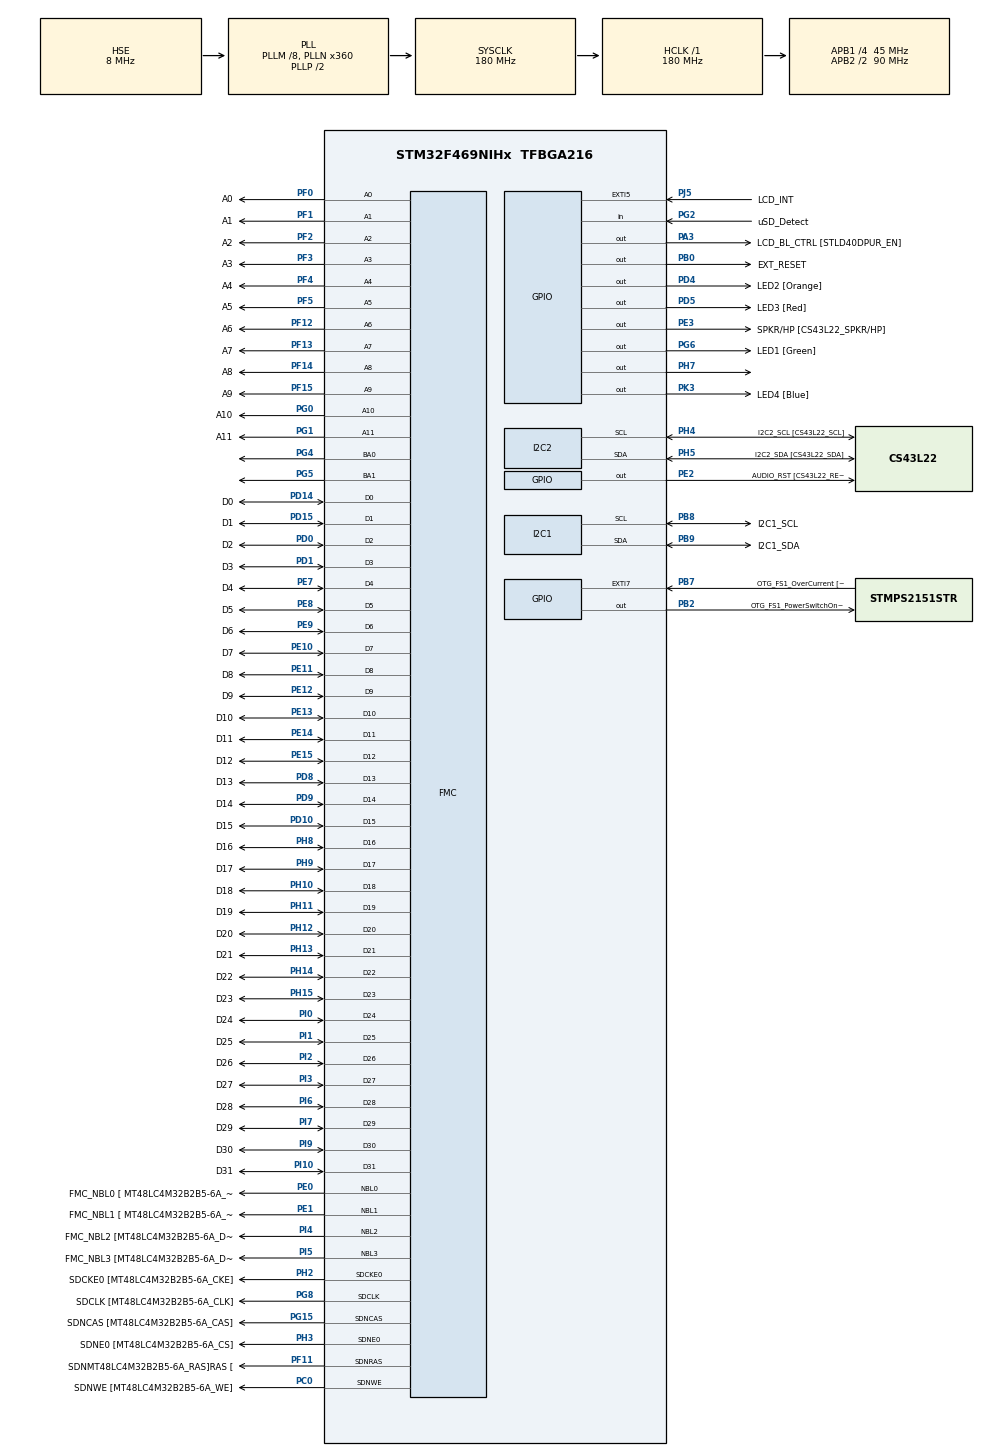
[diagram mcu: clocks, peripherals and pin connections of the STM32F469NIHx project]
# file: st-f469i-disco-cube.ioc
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PF5.GPIO_PuPd=GPIO_NOPULL
PC10.GPIO_PuPd=GPIO_NOPULL
FMC.SDClockPeriod1=FMC_SDRAM_CLOCK_PERIOD_2
SH.FMC_A0.0=FMC_A0,12b-sda1
PB10.GPIO_PuPd=GPIO_PULLUP
PH15.GPIO_Label=D23
NVIC.TIM6_DAC_IRQn=true\:0\:0\:false\:false\:true\:false\:true
PA10.GPIO_PuPd=GPIO_NOPULL
PG8.Signal=FMC_SDCLK
DSIHOST_D0N.Mode=DSIHost_Video
PG0.Signal=FMC_A10
PA3.GPIO_PuPd=GPIO_NOPULL
PE8.GPIO_Speed_High_Default=GPIO_SPEED_FREQ_VERY_HIGH
PE10.GPIO_PuPd=GPIO_NOPULL
PD10.GPIO_PuPd=GPIO_NOPULL
SH.FMC_D5_DA5.0=FMC_D5,sd-32b-d1
PF10.GPIO_PuPd=GPIO_NOPULL
PI10.GPIO_PuPd=GPIO_NOPULL
PH10.GPIO_PuPd=GPIO_NOPULL
PH13.GPIO_Mode=GPIO_MODE_AF_PP
SH.FMC_D9_DA9.0=FMC_D9,sd-32b-d1
PD0.GPIO_Speed_High_Default=GPIO_SPEED_FREQ_VERY_HIGH
DSIHOST_D0P.Signal=DSIHOST_D0P
SH.FMC_D25.0=FMC_D25,sd-32b-d1
PE13.GPIO_Mode=GPIO_MODE_AF_PP
PF13.GPIO_Mode=GPIO_MODE_AF_PP
PG15.GPIO_Label=SDNCAS [MT48LC4M32B2B5-6A_CAS]
PF7.Signal=QUADSPI_BK1_IO2
NVIC.DMA2D_IRQn=true\:0\:0\:false\:false\:true\:true\:true
SH.FMC_SDNWE.0=FMC_SDNWE,12b-sda1
PH9.Signal=FMC_D17
PG7.GPIO_Mode=GPIO_MODE_AF_PP
SH.FMC_D11_DA11.0=FMC_D11,sd-32b-d1
PD9.GPIO_Speed_High_Default=GPIO_SPEED_FREQ_VERY_HIGH
RCC.APB2TimFreq_Value=180000000
PB6.Signal=QUADSPI_BK1_NCS
PD0.Signal=FMC_D2_DA2
PD8.Signal=FMC_D13_DA13
PE1.Signal=FMC_NBL1
PI5.GPIO_Mode=GPIO_MODE_AF_PP
PF1.GPIO_Label=A1
PI4.GPIO_Label=FMC_NBL2 [MT48LC4M32B2B5-6A_DQM2]
PD1.GPIO_Label=D3
FMC.SelfRefreshTime1=4
PF12.GPIO_Label=A6
LTDC.PixelFormat_L0=LTDC_PIXEL_FORMAT_RGB888
PE9.Signal=FMC_D6_DA6
DSIHOST_D1N.Signal=DSIHOST_D1N
SH.FMC_A2.0=FMC_A2,12b-sda1
PE4.GPIO_Label=SAI1_FSA [CS43L22_LRCK]
PD14.GPIO_PuPd=GPIO_NOPULL
SH.FMC_D1_DA1.0=FMC_D1,sd-32b-d1
PK3.GPIO_ModeDefaultOutputPP=GPIO_MODE_OUTPUT_OD
PH14.GPIO_PuPd=GPIO_NOPULL
PF1.GPIO_Mode=GPIO_MODE_AF_PP
PF14.GPIO_PuPd=GPIO_NOPULL
PG0.GPIO_PuPd=GPIO_NOPULL
PH3.GPIO_PuPd=GPIO_NOPULL
PI2.GPIO_PuPd=GPIO_NOPULL
PE9.GPIO_Mode=GPIO_MODE_AF_PP
Mcu.Package=TFBGA216
PB9.Signal=I2C1_SDA
NVIC.TimeBase=TIM6_DAC_IRQn
PI9.GPIO_Mode=GPIO_MODE_AF_PP
PI2.GPIO_Speed_High_Default=GPIO_SPEED_FREQ_VERY_HIGH
NVIC.TimeBaseIP=TIM6
PA10.Signal=USB_OTG_FS_ID
SH.FMC_D27.0=FMC_D27,sd-32b-d1
PE12.GPIO_Label=D9
FMC.WriteRecoveryTime1=3
RCC.APB2CLKDivider=RCC_HCLK_DIV2
PH3.GPIO_Speed_High_Default=GPIO_SPEED_FREQ_VERY_HIGH
RCC.APB1TimFreq_Value=90000000
PD5.GPIO_Speed=GPIO_SPEED_FREQ_LOW
PH5.GPIO_Speed=GPIO_SPEED_FREQ_VERY_HIGH
PB0.GPIO_ModeDefaultOutputPP=GPIO_MODE_OUTPUT_PP
FMC.RowCycleDelay1=7
DSIHOST_D1P.GPIO_Label=DSI_D1_P
PF9.GPIO_PuPd=GPIO_NOPULL
PD15.Signal=FMC_D1_DA1
PE7.GPIO_Speed_High_Default=GPIO_SPEED_FREQ_VERY_HIGH
PC8.GPIO_Mode=GPIO_MODE_AF_PP
PI5.GPIO_PuPd=GPIO_NOPULL
SH.FMC_A4.0=FMC_A4,12b-sda1
PH10.GPIO_Speed_High_Default=GPIO_SPEED_FREQ_VERY_HIGH
PH13.Signal=FMC_D21
PI3.GPIO_Speed_High_Default=GPIO_SPEED_FREQ_VERY_HIGH
PD1.GPIO_Speed_High_Default=GPIO_SPEED_FREQ_VERY_HIGH
PF4.GPIO_Mode=GPIO_MODE_AF_PP
PG5.Signal=FMC_A15_BA1
PE9.GPIO_Speed_High_Default=GPIO_SPEED_FREQ_VERY_HIGH
SH.FMC_D10_DA10.0=FMC_D10,sd-32b-d1
PB6.GPIO_PuPd=GPIO_NOPULL
PI6.GPIO_PuPd=GPIO_NOPULL
SH.FMC_D16.0=FMC_D16,sd-32b-d1
PF5.GPIO_Mode=GPIO_MODE_AF_PP
PG8.GPIO_PuPd=GPIO_NOPULL
PF8.GPIO_Label=QSPI_BK1_IO0 [N25Q128A13EF840F_DQ0]
PD10.Signal=FMC_D15_DA15
PB8.GPIO_Label=I2C1_SCL
PC10.GPIO_Mode=GPIO_MODE_AF_PP
PB10.GPIO_Mode=GPIO_MODE_AF_PP
PE15.GPIO_Speed_High_Default=GPIO_SPEED_FREQ_VERY_HIGH
SH.FMC_D29.0=FMC_D29,sd-32b-d1
PE8.GPIO_Label=D5
PH11.GPIO_Label=D19
PF5.GPIO_Speed_High_Default=GPIO_SPEED_FREQ_VERY_HIGH
PE2.GPIO_PuPd=GPIO_NOPULL
PI0.GPIO_Speed_High_Default=GPIO_SPEED_FREQ_VERY_HIGH
PF10.GPIO_Mode=GPIO_MODE_AF_PP
PE1.GPIO_Label=FMC_NBL1 [ MT48LC4M32B2B5-6A_DQM1]
PD14.GPIO_Speed_High_Default=GPIO_SPEED_FREQ_VERY_HIGH
PF13.GPIO_PuPd=GPIO_NOPULL
PI7.Signal=FMC_D29
FMC.ReadBurst1=FMC_SDRAM_RBURST_ENABLE
SH.FMC_A6.0=FMC_A6,12b-sda1
PE14.Signal=FMC_D11_DA11
PD4.GPIO_Speed=GPIO_SPEED_FREQ_LOW
PH4.GPIO_Speed=GPIO_SPEED_FREQ_VERY_HIGH
PG7.GPIO_Label=SAI1_MCLKA [CS43L22_MCLK]
PI2.Signal=FMC_D26
PF4.GPIO_Label=A4
PC9.GPIO_PuPd=GPIO_NOPULL
PE3.GPIO_PuPd=GPIO_NOPULL
PF13.Signal=FMC_A7
PG14.GPIO_PuPd=GPIO_NOPULL
SH.FMC_NBL2.0=FMC_NBL2,Sd4ByteEnable1
SH.FMC_D18.0=FMC_D18,sd-32b-d1
PC8.GPIO_PuPd=GPIO_NOPULL
PE5.GPIO_Label=SAI1_SCKA [CS43L22_CLK]
PC12.GPIO_Label=uSD_CLK
ProjectManager.HeapSize=0x200
DSIHOST_CKP.GPIO_Label=DSI_CK_P
PD0.GPIO_PuPd=GPIO_NOPULL
NVIC.PriorityGroup=NVIC_PRIORITYGROUP_4
PF0.GPIO_Label=A0
PI1.GPIO_Mode=GPIO_MODE_AF_PP
PH14.GPIO_Mode=GPIO_MODE_AF_PP
PE3.Signal=GPIO_Output
PC15/OSC32_OUT.Signal=RCC_OSC32_OUT
PF4.Signal=FMC_A4
DSIHOST_D0P.GPIO_Label=DSI_D0_P
PD2.Signal=SDIO_CMD
PD14.GPIO_Mode=GPIO_MODE_AF_PP
PH9.GPIO_Mode=GPIO_MODE_AF_PP
PI1.GPIO_Label=D25
DSIHOST.LPVerticalSyncActiveEnable=DSI_LP_VSYNC_ENABLE
Mcu.Family=STM32F4
PK3.Signal=GPIO_Output
SH.FMC_A8.0=FMC_A8,12b-sda1
PI4.GPIO_Mode=GPIO_MODE_AF_PP
RCC.PLLDSIIDF=DSI_PLL_IN_DIV2
PH14.Signal=FMC_D22
PH10.Signal=FMC_D18
SH.FMC_D14_DA14.0=FMC_D14,sd-32b-d1
PG2.Signal=GPIO_Input
PE11.GPIO_Label=D8
PE2.GPIO_Speed=GPIO_SPEED_FREQ_LOW
PD0.GPIO_Label=D2
PF9.GPIO_Speed=GPIO_SPEED_FREQ_VERY_HIGH
PC14/OSC32_IN.Mode=LSE-External-Oscillator
PD2.GPIO_Mode=GPIO_MODE_AF_PP
SH.FMC_A14_BA0.0=FMC_BA0,FourSdramBanks1
SH.FMC_A11.0=FMC_A11,12b-sda1
PG9.GPIO_Speed=GPIO_SPEED_FREQ_VERY_HIGH
PJ2.GPIO_Speed=GPIO_SPEED_FREQ_VERY_HIGH
PB7.GPIO_ModeDefaultEXTI=GPIO_MODE_IT_RISING
PD8.GPIO_PuPd=GPIO_NOPULL
PI9.GPIO_Speed_High_Default=GPIO_SPEED_FREQ_VERY_HIGH
PG15.Signal=FMC_SDNCAS
PJ5.GPIO_Label=LCD_INT
PH11.GPIO_PuPd=GPIO_NOPULL
PD13.Signal=S_TIM4_CH2
PC11.GPIO_PuPd=GPIO_NOPULL
PJ2.Signal=DSIHOST_TE
PE11.GPIO_PuPd=GPIO_NOPULL
PF11.GPIO_PuPd=GPIO_NOPULL
PG15.GPIO_Speed_High_Default=GPIO_SPEED_FREQ_VERY_HIGH
SH.FMC_NBL1.0=FMC_NBL1,Sd4ByteEnable1
PF15.GPIO_Speed_High_Default=GPIO_SPEED_FREQ_VERY_HIGH
PA9.GPIO_Mode=GPIO_MODE_AF_PP
RCC.HSE_VALUE=8000000
PI2.GPIO_Mode=GPIO_MODE_AF_PP
PE2.GPIO_ModeDefaultOutputPP=GPIO_MODE_OUTPUT_PP
FMC.ExitSelfRefreshDelay1=7
PF7.GPIO_Mode=GPIO_MODE_AF_PP
PE13.GPIO_PuPd=GPIO_NOPULL
PB3.GPIO_PuPd=GPIO_NOPULL
PF7.GPIO_Speed=GPIO_SPEED_FREQ_VERY_HIGH
DSIHOST.LPHorizontalFrontPorchEnable=DSI_LP_HFP_ENABLE
PF8.GPIO_PuPd=GPIO_NOPULL
PA14.Mode=Serial_Wire
DSIHOST_D1P.Signal=DSIHOST_D1P
PB2/BOOT1.GPIO_PuPd=GPIO_NOPULL
PF11.Signal=FMC_SDNRAS
PC11.GPIO_Label=uSD_D3
PB7.Signal=GPXTI7
PG7.GPIO_PuPd=GPIO_NOPULL
PH12.GPIO_Mode=GPIO_MODE_AF_PP
PJ5.GPIO_PuPd=GPIO_NOPULL
PG6.GPIO_ModeDefaultOutputPP=GPIO_MODE_OUTPUT_OD
PB7.GPIO_Label=OTG_FS1_OverCurrent [STMPS2151STR_FAULT]
PD6.GPIO_Mode=GPIO_MODE_AF_PP
PD13.GPIO_Label=MIC_CK [MP34DT01TR_CLK]
PD5.GPIO_Label=LED3 [Red]
PG1.GPIO_PuPd=GPIO_NOPULL
PF8.Signal=QUADSPI_BK1_IO0
PG0.GPIO_Label=A10
PI0.GPIO_Label=D24
PA10.GPIO_Speed=GPIO_SPEED_FREQ_VERY_HIGH
PH11.GPIO_Speed_High_Default=GPIO_SPEED_FREQ_VERY_HIGH
PD0.GPIO_Mode=GPIO_MODE_AF_PP
DSIHOST_CKN.Signal=DSIHOST_CKN
PG14.GPIO_Mode=GPIO_MODE_AF_PP
PE14.GPIO_Mode=GPIO_MODE_AF_PP
PH2.Mode=SdramChipSelect1_1
PE7.Signal=FMC_D4_DA4
PD6.Signal=SAI1_SD_A
PF3.GPIO_Label=A3
PE2.GPIO_Label=AUDIO_RST [CS43L22_RESET]
PH15.GPIO_PuPd=GPIO_NOPULL
PA12.GPIO_Speed=GPIO_SPEED_FREQ_VERY_HIGH
DSIHOST_D0P.Mode=DSIHost_Video
PG2.GPIO_Label=uSD_Detect
PA3.Signal=GPIO_Output
PE0.GPIO_PuPd=GPIO_NOPULL
PG1.GPIO_Mode=GPIO_MODE_AF_PP
SH.FMC_D20.0=FMC_D20,sd-32b-d1
PC0.GPIO_Speed_High_Default=GPIO_SPEED_FREQ_VERY_HIGH
PD15.GPIO_Label=D1
PG7.Signal=SAI1_MCLK_A
PD13.GPIO_ModeDefaultPP=GPIO_MODE_AF_PP
PH12.GPIO_Label=D20
PC9.GPIO_Label=uSD_D1
PC11.Signal=SDIO_D3
PC8.Signal=SDIO_D0
PF10.GPIO_Speed=GPIO_SPEED_FREQ_VERY_HIGH
SH.FMC_D31.0=FMC_D31,sd-32b-d1
PH4.GPIO_PuPdOD=GPIO_PULLUP
PJ2.GPIO_PuPd=GPIO_NOPULL
PE14.GPIO_Label=D11
PD9.Signal=FMC_D14_DA14
PD8.GPIO_Speed_High_Default=GPIO_SPEED_FREQ_VERY_HIGH
PA9.GPIO_PuPd=GPIO_NOPULL
PA12.GPIO_Label=USB_FS1_P
PD8.GPIO_Label=D13
PB0.GPIO_Speed=GPIO_SPEED_FREQ_LOW
PG8.GPIO_Label=SDCLK [MT48LC4M32B2B5-6A_CLK]
PA13.Signal=SYS_JTMS-SWDIO
DSIHOST.LPHorizontalBackPorchEnable=DSI_LP_HBP_ENABLE
PD4.GPIO_PuPd=GPIO_NOPULL
PB2/BOOT1.Signal=GPIO_Output
PF6.Signal=QUADSPI_BK1_IO3
PC9.GPIO_Mode=GPIO_MODE_AF_PP
PB10.GPIO_Label=STLK_RX [STLINK V2-1_U2_RX]
SH.FMC_D13_DA13.0=FMC_D13,sd-32b-d1
PF0.GPIO_Speed_High_Default=GPIO_SPEED_FREQ_VERY_HIGH
PH8.Signal=FMC_D16
PB9.Mode=I2C
PG2.GPIO_Mode=GPIO_MODE_INPUT
RCC.USBFreq_Value=36000000
PF9.GPIO_Label=QSPI_BK1_IO1 [N25Q128A13EF840F_DQ1]
PD10.GPIO_Label=D15
PE10.GPIO_Speed_High_Default=GPIO_SPEED_FREQ_VERY_HIGH
PH10.GPIO_Mode=GPIO_MODE_AF_PP
DSIHOST_CKP.Signal=DSIHOST_CKP
PE10.GPIO_Mode=GPIO_MODE_AF_PP
board=STM32F469I-DISCO
PD13.GPIO_Speed=GPIO_SPEED_FREQ_LOW
RCC.VCOOutputFreq_Value=360000000
PI9.Signal=FMC_D30
PH4.GPIO_Label=I2C2_SCL [CS43L22_SCL]
SH.FMC_D22.0=FMC_D22,sd-32b-d1
PH13.GPIO_PuPd=GPIO_NOPULL
RCC.PLLDSINDIV=125
PI4.Signal=FMC_NBL2
PE11.GPIO_Mode=GPIO_MODE_AF_PP
SH.FMC_D12_DA12.0=FMC_D12,sd-32b-d1
PF15.GPIO_Label=A9
PD5.GPIO_PuPd=GPIO_NOPULL
PE14.GPIO_PuPd=GPIO_NOPULL
PF1.Signal=FMC_A1
PF8.GPIO_Mode=GPIO_MODE_AF_PP
PE0.Signal=FMC_NBL0
PE7.GPIO_Label=D4
PE12.Signal=FMC_D9_DA9
PE12.GPIO_Mode=GPIO_MODE_AF_PP
PI1.GPIO_Speed_High_Default=GPIO_SPEED_FREQ_VERY_HIGH
DSIHOST_CKN.GPIO_Label=DSI_CK_N
RCC.SYSCLKFreq_VALUE=180000000
PI9.GPIO_PuPd=GPIO_NOPULL
PI10.GPIO_Speed_High_Default=GPIO_SPEED_FREQ_VERY_HIGH
PI7.GPIO_Mode=GPIO_MODE_AF_PP
PJ5.Signal=GPXTI5
DSIHOST.LPVerticalBackPorchEnable=DSI_LP_VBP_ENABLE
PE15.GPIO_PuPd=GPIO_NOPULL
PF9.GPIO_Mode=GPIO_MODE_AF_PP
RCC.PLLQ=6
PI6.GPIO_Mode=GPIO_MODE_AF_PP
PI3.GPIO_Label=D27
PH3.Signal=FMC_SDNE0
RCC.PLLM=8
RCC.PLLN=360
DSIHOST.StopWaitTime=10
PE5.GPIO_Speed=GPIO_SPEED_FREQ_LOW
PA9.GPIO_Speed=GPIO_SPEED_FREQ_VERY_HIGH
PH12.GPIO_PuPd=GPIO_NOPULL
PG0.GPIO_Mode=GPIO_MODE_AF_PP
PH5.Mode=I2C
PD2.GPIO_Speed_High_Default=GPIO_SPEED_FREQ_VERY_HIGH
PH12.GPIO_Speed_High_Default=GPIO_SPEED_FREQ_VERY_HIGH
PB8.GPIO_Speed=GPIO_SPEED_FREQ_VERY_HIGH
PJ2.GPIO_Label=DSI_TE
PG14.GPIO_Speed=GPIO_SPEED_FREQ_VERY_HIGH
PD6.GPIO_Speed=GPIO_SPEED_FREQ_LOW
PB0.GPIO_PuPd=GPIO_NOPULL
PA3.GPIO_Label=LCD_BL_CTRL [STLD40DPUR_EN]
PD6.GPIO_PuPd=GPIO_NOPULL
PA11.GPIO_Speed=GPIO_SPEED_FREQ_VERY_HIGH
PH15.GPIO_Mode=GPIO_MODE_AF_PP
PF15.GPIO_Mode=GPIO_MODE_AF_PP
SH.FMC_D7_DA7.0=FMC_D7,sd-32b-d1
PE15.GPIO_Mode=GPIO_MODE_AF_PP
PD1.GPIO_Mode=GPIO_MODE_AF_PP
PD15.GPIO_Mode=GPIO_MODE_AF_PP
VP_SYS_VS_tim6.Mode=TIM6
SH.FMC_D24.0=FMC_D24,sd-32b-d1
PH12.Signal=FMC_D20
FMC.RCDDelay1=2
PI3.GPIO_Mode=GPIO_MODE_AF_PP
PG2.GPIO_PuPd=GPIO_NOPULL
PG4.Signal=FMC_A14_BA0
PC12.Signal=SDIO_CK
PA14.GPIO_Label=SWCLK
PG6.GPIO_Label=LED1 [Green]
PE8.GPIO_PuPd=GPIO_NOPULL
FMC.LoadToActiveDelay1=2
DSIHOST_D1P.Mode=DSIHost_Video
PI6.GPIO_Label=D28
PB6.GPIO_Label=QSPI_BK1_NCS [N25Q128A13EF840F_S]
PA3.GPIO_Speed=GPIO_SPEED_FREQ_LOW
PD6.GPIO_Label=MIC_DATA [MP34DT01TR_DOUT]
PB3.GPIO_Speed=GPIO_SPEED_FREQ_LOW
PF6.GPIO_Label=QSPI_BK1_IO3 [N25Q128A13EF840F_DQ3]
RCC.SYSCLKSource=RCC_SYSCLKSOURCE_PLLCLK
PG15.GPIO_Mode=GPIO_MODE_AF_PP
PH14.GPIO_Speed_High_Default=GPIO_SPEED_FREQ_VERY_HIGH
PB11.GPIO_Speed=GPIO_SPEED_FREQ_VERY_HIGH
SH.FMC_A15_BA1.0=FMC_BA1,FourSdramBanks1
PH8.GPIO_Mode=GPIO_MODE_AF_PP
PI0.GPIO_PuPd=GPIO_NOPULL
PH5.Signal=I2C2_SDA
PC10.GPIO_Speed_High_Default=GPIO_SPEED_FREQ_VERY_HIGH
PD4.Signal=GPIO_Output
PB2/BOOT1.GPIO_Label=OTG_FS1_PowerSwitchOn [STMPS2151STR_En]
DSIHOST_CKP.Mode=DSIHost_Video
PH1/OSC_OUT.Signal=RCC_OSC_OUT
PE5.Signal=SAI1_SCK_A
PG0.GPIO_Speed_High_Default=GPIO_SPEED_FREQ_VERY_HIGH
PJ2.GPIO_Mode=GPIO_MODE_AF_PP
PF10.GPIO_Label=QSPI_CLK [N25Q128A13EF840F_C]
PH10.GPIO_Label=D18
PE11.GPIO_Speed_High_Default=GPIO_SPEED_FREQ_VERY_HIGH
PG6.GPIO_PuPd=GPIO_NOPULL
SH.FMC_D26.0=FMC_D26,sd-32b-d1
PH11.GPIO_Mode=GPIO_MODE_AF_PP
PF11.GPIO_Mode=GPIO_MODE_AF_PP
PI6.Signal=FMC_D28
PI3.Signal=FMC_D27
SH.S_TIM4_CH2.0=TIM4_CH2
PF13.GPIO_Speed_High_Default=GPIO_SPEED_FREQ_VERY_HIGH
PD4.GPIO_ModeDefaultOutputPP=GPIO_MODE_OUTPUT_OD
PE2.Signal=GPIO_Output
PF3.Signal=FMC_A3
PE10.Signal=FMC_D7_DA7
PF1.GPIO_Speed_High_Default=GPIO_SPEED_FREQ_VERY_HIGH
VP_TIM1_VS_ClockSourceINT.Mode=Internal
PH13.GPIO_Speed_High_Default=GPIO_SPEED_FREQ_VERY_HIGH
PB2/BOOT1.GPIO_ModeDefaultOutputPP=GPIO_MODE_OUTPUT_PP
DSIHOST.LPVerticalFrontPorchEnable=DSI_LP_VFP_ENABLE
PI7.GPIO_PuPd=GPIO_NOPULL
DSIHOST_D1N.GPIO_Label=DSI_D1_N
PF3.GPIO_PuPd=GPIO_NOPULL
PB8.GPIO_PuPdOD=GPIO_PULLUP
SH.FMC_A1.0=FMC_A1,12b-sda1
PH2.Signal=FMC_SDCKE0
PI7.GPIO_Speed_High_Default=GPIO_SPEED_FREQ_VERY_HIGH
SH.FMC_SDCLK.0=FMC_SDCLK,12b-sda1
PF14.Signal=FMC_A8
VP_DMA2D_VS_DMA2D.Mode=DMA2D_Activate
PG9.GPIO_Mode=GPIO_MODE_AF_PP
PF6.GPIO_Mode=GPIO_MODE_AF_PP
PH8.GPIO_Speed_High_Default=GPIO_SPEED_FREQ_VERY_HIGH
PC12.GPIO_PuPd=GPIO_NOPULL
PB11.GPIO_Mode=GPIO_MODE_AF_PP
PA12.GPIO_PuPd=GPIO_NOPULL
PE10.GPIO_Label=D7
PD9.GPIO_PuPd=GPIO_NOPULL
SH.FMC_D3_DA3.0=FMC_D3,sd-32b-d1
PG6.GPIO_Speed=GPIO_SPEED_FREQ_LOW
PE12.GPIO_PuPd=GPIO_NOPULL
PI10.GPIO_Label=D31
PD8.GPIO_Mode=GPIO_MODE_AF_PP
PB7.GPIO_PuPd=GPIO_NOPULL
PH15.Signal=FMC_D23
PA3.GPIO_ModeDefaultOutputPP=GPIO_MODE_OUTPUT_PP
SH.FMC_D28.0=FMC_D28,sd-32b-d1
PD9.GPIO_Label=D14
PD2.GPIO_PuPd=GPIO_NOPULL
PG9.GPIO_PuPd=GPIO_NOPULL
PG9.Signal=USART6_RX
PA9.GPIO_Label=VBUS_FS1
PD9.GPIO_Mode=GPIO_MODE_AF_PP
PB11.GPIO_Label=STLK_TX [STLINK V2-1_U2_TX]
PD1.Signal=FMC_D3_DA3
PA11.GPIO_Label=USB_FS1_N
PE1.GPIO_PuPd=GPIO_NOPULL
PF14.GPIO_Label=A8
PD1.GPIO_PuPd=GPIO_NOPULL
PC0.Signal=FMC_SDNWE
RCC.APB1CLKDivider=RCC_HCLK_DIV4
PG1.GPIO_Speed_High_Default=GPIO_SPEED_FREQ_VERY_HIGH
PF13.GPIO_Label=A7
PF11.GPIO_Speed_High_Default=GPIO_SPEED_FREQ_VERY_HIGH
PD10.GPIO_Speed_High_Default=GPIO_SPEED_FREQ_VERY_HIGH
SH.FMC_A3.0=FMC_A3,12b-sda1
FMC.CASLatency1=FMC_SDRAM_CAS_LATENCY_3
PF2.GPIO_Mode=GPIO_MODE_AF_PP
SH.FMC_D15_DA15.0=FMC_D15,sd-32b-d1
PI3.GPIO_PuPd=GPIO_NOPULL
PA9.Signal=USB_OTG_FS_VBUS
PE9.GPIO_Label=D6
SH.FMC_D17.0=FMC_D17,sd-32b-d1
PA0/WKUP.Mode=SYS_WakeUp0
PB10.Signal=USART3_TX
RCC.USBCLockSelection=RCC_CLK48CLKSOURCE_PLLSAIP
PH9.GPIO_Label=D17
PI9.GPIO_Label=D30
PI0.GPIO_Mode=GPIO_MODE_AF_PP
PI6.GPIO_Speed_High_Default=GPIO_SPEED_FREQ_VERY_HIGH
PE15.Signal=FMC_D12_DA12
PE8.Signal=FMC_D5_DA5
PI1.Signal=FMC_D25
PC11.GPIO_Mode=GPIO_MODE_AF_PP
PA0/WKUP.GPIO_Label=WAKEUP [B2]
PB3.GPIO_Mode=GPIO_MODE_AF_PP
SH.FMC_SDNCAS.0=FMC_SDNCAS,12b-sda1
PA13.Mode=Serial_Wire
PG14.GPIO_Label=ARDUINO USART6_TX
PF14.GPIO_Speed_High_Default=GPIO_SPEED_FREQ_VERY_HIGH
PH4.Mode=I2C
PE4.GPIO_PuPd=GPIO_NOPULL
PF7.GPIO_PuPd=GPIO_NOPULL
PC12.GPIO_Speed_High_Default=GPIO_SPEED_FREQ_VERY_HIGH
PH14.GPIO_Label=D22
PC8.GPIO_Speed_High_Default=GPIO_SPEED_FREQ_VERY_HIGH
PC12.GPIO_Mode=GPIO_MODE_AF_PP
PE13.GPIO_Label=D10
PE3.GPIO_Speed=GPIO_SPEED_FREQ_LOW
PE3.GPIO_ModeDefaultOutputPP=GPIO_MODE_OUTPUT_PP
SH.FMC_A5.0=FMC_A5,12b-sda1
PA11.Signal=USB_OTG_FS_DM
PK3.GPIO_Label=LED4 [Blue]
PE12.GPIO_Speed_High_Default=GPIO_SPEED_FREQ_VERY_HIGH
PF9.Signal=QUADSPI_BK1_IO1
PB8.Mode=I2C
PF6.GPIO_PuPd=GPIO_NOPULL
PG8.GPIO_Speed_High_Default=GPIO_SPEED_FREQ_VERY_HIGH
PF12.GPIO_PuPd=GPIO_NOPULL
PI4.GPIO_PuPd=GPIO_NOPULL
PD5.GPIO_ModeDefaultOutputPP=GPIO_MODE_OUTPUT_OD
SH.FMC_NBL3.0=FMC_NBL3,Sd4ByteEnable1
PB6.GPIO_Speed=GPIO_SPEED_FREQ_VERY_HIGH
PB0.Signal=GPIO_Output
SH.FMC_D19.0=FMC_D19,sd-32b-d1
PE0.GPIO_Mode=GPIO_MODE_AF_PP
PG15.GPIO_PuPd=GPIO_NOPULL
PD2.GPIO_Label=uSD_CMD
PF3.GPIO_Mode=GPIO_MODE_AF_PP
PH2.GPIO_Label=SDCKE0 [MT48LC4M32B2B5-6A_CKE]
PF6.GPIO_Speed=GPIO_SPEED_FREQ_VERY_HIGH
PF2.GPIO_Speed_High_Default=GPIO_SPEED_FREQ_VERY_HIGH
PE7.GPIO_PuPd=GPIO_NOPULL
RCC.CortexFreq_Value=180000000
PG6.Signal=GPIO_Output
PB10.GPIO_Speed=GPIO_SPEED_FREQ_VERY_HIGH
PB6.GPIO_Mode=GPIO_MODE_AF_PP
PF4.GPIO_Speed_High_Default=GPIO_SPEED_FREQ_VERY_HIGH
PC10.Signal=SDIO_D2
PF4.GPIO_PuPd=GPIO_NOPULL
SH.FMC_NBL0.0=FMC_NBL0,Sd4ByteEnable1
PI4.GPIO_Speed_High_Default=GPIO_SPEED_FREQ_VERY_HIGH
PC0.GPIO_Label=SDNWE [MT48LC4M32B2B5-6A_WE]
SH.FMC_D6_DA6.0=FMC_D6,sd-32b-d1
PA0/WKUP.Signal=SYS_WKUP
PB0.GPIO_Label=EXT_RESET
PA11.GPIO_PuPd=GPIO_NOPULL
PH5.GPIO_Label=I2C2_SDA [CS43L22_SDA]
PI5.GPIO_Label=FMC_NBL3 [MT48LC4M32B2B5-6A_DQM3]
PE14.GPIO_Speed_High_Default=GPIO_SPEED_FREQ_VERY_HIGH
PB11.GPIO_PuPd=GPIO_PULLUP
PB11.Signal=USART3_RX
PG8.GPIO_Mode=GPIO_MODE_AF_PP
ProjectManager.StackSize=0x400
PH2.GPIO_PuPd=GPIO_NOPULL
PH3.Mode=SdramChipSelect1_1
SH.FMC_A7.0=FMC_A7,12b-sda1
PA12.Signal=USB_OTG_FS_DP
PE5.GPIO_PuPd=GPIO_NOPULL
DSIHOST.LPVerticalActiveEnable=DSI_LP_VACT_ENABLE
PE1.GPIO_Mode=GPIO_MODE_AF_PP
PH0/OSC_IN.Mode=HSE-External-Oscillator
RCC.HCLKFreq_Value=180000000
PH5.GPIO_Mode=GPIO_MODE_AF_OD
PF11.GPIO_Label=SDNMT48LC4M32B2B5-6A_RAS]RAS [
PF2.GPIO_PuPd=GPIO_NOPULL
PF12.Signal=FMC_A6
PC9.GPIO_Speed_High_Default=GPIO_SPEED_FREQ_VERY_HIGH
SH.FMC_A10.0=FMC_A10,12b-sda1
RCC.AHBFreq_Value=180000000
DSIHOST_D1N.Mode=DSIHost_Video
SH.FMC_D8_DA8.0=FMC_D8,sd-32b-d1
FMC.RPDelay1=2
PJ5.GPIO_ModeDefaultEXTI=GPIO_MODE_IT_RISING
SH.FMC_D2_DA2.0=FMC_D2,sd-32b-d1
PE13.Signal=FMC_D10_DA10
PF7.GPIO_Label=QSPI_BK1_IO2 [N25Q128A13EF840F_DQ2]
PI1.GPIO_PuPd=GPIO_NOPULL
PE0.GPIO_Speed_High_Default=GPIO_SPEED_FREQ_VERY_HIGH
PI5.Signal=FMC_NBL3
PE4.GPIO_Speed=GPIO_SPEED_FREQ_LOW
PI0.Signal=FMC_D24
PA10.GPIO_Label=USB_FS1_ID
SH.FMC_SDNRAS.0=FMC_SDNRAS,12b-sda1
LTDC.ActiveW=800
PE4.Signal=SAI1_FS_A
PH1/OSC_OUT.Mode=HSE-External-Oscillator
PF12.GPIO_Mode=GPIO_MODE_AF_PP
SH.FMC_D0_DA0.0=FMC_D0,sd-32b-d1
PC14/OSC32_IN.Signal=RCC_OSC32_IN
PH9.GPIO_PuPd=GPIO_NOPULL
PD15.GPIO_PuPd=GPIO_NOPULL
PF15.GPIO_PuPd=GPIO_NOPULL
PF5.GPIO_Label=A5
PF3.GPIO_Speed_High_Default=GPIO_SPEED_FREQ_VERY_HIGH
SH.FMC_A9.0=FMC_A9,12b-sda1
SH.FMC_D4_DA4.0=FMC_D4,sd-32b-d1
PE8.GPIO_Mode=GPIO_MODE_AF_PP
PE0.GPIO_Label=FMC_NBL0 [ MT48LC4M32B2B5-6A_DQM0]
RCC.PLLSAIN=216
PH3.GPIO_Label=SDNE0 [MT48LC4M32B2B5-6A_CS]
PF5.Signal=FMC_A5
RCC.PLLSAIP=RCC_PLLSAIP_DIV6
PB2/BOOT1.GPIO_Speed=GPIO_SPEED_FREQ_LOW
PH7.Signal=GPIO_Output
RCC.PLLSAIQ=2
PB9.GPIO_Speed=GPIO_SPEED_FREQ_VERY_HIGH
PE13.GPIO_Speed_High_Default=GPIO_SPEED_FREQ_VERY_HIGH
SH.FMC_D30.0=FMC_D30,sd-32b-d1
PF0.Signal=FMC_A0
PI2.GPIO_Label=D26
PC0.GPIO_PuPd=GPIO_NOPULL
PF0.GPIO_Mode=GPIO_MODE_AF_PP
PB3.GPIO_Label=I2S3_CK
RCC.PLLSourceVirtual=RCC_PLLSOURCE_HSE
PH2.GPIO_Speed_High_Default=GPIO_SPEED_FREQ_VERY_HIGH
PH15.GPIO_Speed_High_Default=GPIO_SPEED_FREQ_VERY_HIGH
PB9.GPIO_Label=I2C1_SDA
PC10.GPIO_Label=uSD_D2
PH11.Signal=FMC_D19
PG1.Signal=FMC_A11
PH5.GPIO_PuPdOD=GPIO_PULLUP
PE5.GPIO_Mode=GPIO_MODE_AF_PP
PI10.Signal=FMC_D31
PD5.Signal=GPIO_Output
PA10.GPIO_Mode=GPIO_MODE_AF_PP
PH13.GPIO_Label=D21
PC8.GPIO_Label=uSD_D0
PD10.GPIO_Mode=GPIO_MODE_AF_PP
SH.FMC_D21.0=FMC_D21,sd-32b-d1
PH8.GPIO_Label=D16
PE4.GPIO_Mode=GPIO_MODE_AF_PP
PD15.GPIO_Speed_High_Default=GPIO_SPEED_FREQ_VERY_HIGH
PE15.GPIO_Label=D12
PH4.Signal=I2C2_SCL
ProjectManager.TargetToolchain=Makefile
PC11.GPIO_Speed_High_Default=GPIO_SPEED_FREQ_VERY_HIGH
PF2.Signal=FMC_A2
PH8.GPIO_PuPd=GPIO_NOPULL
PE11.Signal=FMC_D8_DA8
PE7.GPIO_Mode=GPIO_MODE_AF_PP
PI10.GPIO_Mode=GPIO_MODE_AF_PP
PG9.GPIO_Label=USART6_RX
PG14.Signal=USART6_TX
PI5.GPIO_Speed_High_Default=GPIO_SPEED_FREQ_VERY_HIGH
PK3.GPIO_PuPd=GPIO_NOPULL
PG1.GPIO_Label=A11
PB9.GPIO_Mode=GPIO_MODE_AF_OD
DSIHOST.NumberOfLanes=DSI_TWO_DATA_LANES
PA12.GPIO_Mode=GPIO_MODE_AF_PP
PH0/OSC_IN.Signal=RCC_OSC_IN
PG7.GPIO_Speed=GPIO_SPEED_FREQ_LOW
RCC.APB2Freq_Value=90000000
PH2.GPIO_Mode=GPIO_MODE_AF_PP
PC0.GPIO_Mode=GPIO_MODE_AF_PP
LTDC.Layers=0
PD4.GPIO_Label=LED2 [Orange]
PF10.Signal=QUADSPI_CLK
PH3.GPIO_Mode=GPIO_MODE_AF_PP
PF1.GPIO_PuPd=GPIO_NOPULL
PI7.GPIO_Label=D29
PD13.GPIO_PuPd=GPIO_NOPULL
PE1.GPIO_Speed_High_Default=GPIO_SPEED_FREQ_VERY_HIGH
PF15.Signal=FMC_A9
PD14.GPIO_Label=D0
Mcu.Name=STM32F469NIHx
PA13.GPIO_Label=SWDIO
DSIHOST_CKN.Mode=DSIHost_Video
DSIHOST_D0N.GPIO_Label=DSI_D0_N
PD14.Signal=FMC_D0_DA0
PH9.GPIO_Speed_High_Default=GPIO_SPEED_FREQ_VERY_HIGH
PB3.Signal=I2S3_CK
PH4.GPIO_Mode=GPIO_MODE_AF_OD
PF0.GPIO_PuPd=GPIO_NOPULL
PC15/OSC32_OUT.Mode=LSE-External-Oscillator
SH.FMC_D23.0=FMC_D23,sd-32b-d1
PF12.GPIO_Speed_High_Default=GPIO_SPEED_FREQ_VERY_HIGH
PA14.Signal=SYS_JTCK-SWCLK
DSIHOST_D0N.Signal=DSIHOST_D0N
PB9.GPIO_PuPdOD=GPIO_PULLUP
VP_LTDC_DSIMode.Mode=RGB888
PK3.GPIO_Speed=GPIO_SPEED_FREQ_LOW
PF8.GPIO_Speed=GPIO_SPEED_FREQ_VERY_HIGH
PB8.Signal=I2C1_SCL
PE3.GPIO_Label=SPKR/HP [CS43L22_SPKR/HP]
PF14.GPIO_Mode=GPIO_MODE_AF_PP
PC9.Signal=SDIO_D1
PA11.GPIO_Mode=GPIO_MODE_AF_PP
PB8.GPIO_Mode=GPIO_MODE_AF_OD
RCC.APB1Freq_Value=45000000
PE9.GPIO_PuPd=GPIO_NOPULL
PF2.GPIO_Label=A2

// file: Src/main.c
/* USER CODE BEGIN Header */
/**
  ******************************************************************************
  * @file           : main.c
  * @brief          : Main program body
  ******************************************************************************
  * @attention
  *
  * <h2><center>&copy; Copyright (c) 2020 STMicroelectronics.
  * All rights reserved.</center></h2>
  *
  * This software component is licensed by ST under BSD 3-Clause license,
  * the "License"; You may not use this file except in compliance with the
  * License. You may obtain a copy of the License at:
  *                        opensource.org/licenses/BSD-3-Clause
  *
  ******************************************************************************
  */
/* USER CODE END Header */

#include "main.h"

/* USER CODE BEGIN Includes */
#include "app_main.h"
/* USER CODE END Includes */

DMA2D_HandleTypeDef hdma2d;

DSI_HandleTypeDef hdsi;

I2C_HandleTypeDef hi2c1;
I2C_HandleTypeDef hi2c2;

LTDC_HandleTypeDef hltdc;

TIM_HandleTypeDef htim1;

SDRAM_HandleTypeDef hsdram1;

void SystemClock_Config(void);
static void MX_GPIO_Init(void);
static void MX_DMA2D_Init(void);
static void MX_FMC_Init(void);
static void MX_LTDC_Init(void);
static void MX_TIM1_Init(void);
static void MX_DSIHOST_DSI_Init(void);
static void MX_I2C1_Init(void);
static void MX_I2C2_Init(void);

int main(void)
{

  /* MCU Configuration--------------------------------------------------------*/

  /* Reset of all peripherals, Initializes the Flash interface and the Systick. */
  HAL_Init();

  /* Configure the system clock */
  SystemClock_Config();

  /* Initialize all configured peripherals */
  MX_GPIO_Init();
  MX_DMA2D_Init();
  MX_FMC_Init();
  MX_LTDC_Init();
  MX_TIM1_Init();
  MX_DSIHOST_DSI_Init();
  MX_I2C1_Init();
  MX_I2C2_Init();
  /* USER CODE BEGIN 2 */
  app_main();
  /* USER CODE END 2 */

  /* Infinite loop */
  while (1)
  {

  }
}

void SystemClock_Config(void)
{
  RCC_OscInitTypeDef RCC_OscInitStruct = {0};
  RCC_ClkInitTypeDef RCC_ClkInitStruct = {0};
  RCC_PeriphCLKInitTypeDef PeriphClkInitStruct = {0};

  /** Configure the main internal regulator output voltage
  */
  __HAL_RCC_PWR_CLK_ENABLE();
  __HAL_PWR_VOLTAGESCALING_CONFIG(PWR_REGULATOR_VOLTAGE_SCALE1);
  /** Initializes the CPU, AHB and APB busses clocks
  */
  RCC_OscInitStruct.OscillatorType = RCC_OSCILLATORTYPE_HSE;
  RCC_OscInitStruct.HSEState = RCC_HSE_ON;
  RCC_OscInitStruct.PLL.PLLState = RCC_PLL_ON;
  RCC_OscInitStruct.PLL.PLLSource = RCC_PLLSOURCE_HSE;
  RCC_OscInitStruct.PLL.PLLM = 8;
  RCC_OscInitStruct.PLL.PLLN = 360;
  RCC_OscInitStruct.PLL.PLLP = RCC_PLLP_DIV2;
  RCC_OscInitStruct.PLL.PLLQ = 6;
  RCC_OscInitStruct.PLL.PLLR = 2;
  if (HAL_RCC_OscConfig(&RCC_OscInitStruct) != HAL_OK)
  {
    Error_Handler();
  }
  /** Activate the Over-Drive mode
  */
  if (HAL_PWREx_EnableOverDrive() != HAL_OK)
  {
    Error_Handler();
  }
  /** Initializes the CPU, AHB and APB busses clocks
  */
  RCC_ClkInitStruct.ClockType = RCC_CLOCKTYPE_HCLK|RCC_CLOCKTYPE_SYSCLK
                              |RCC_CLOCKTYPE_PCLK1|RCC_CLOCKTYPE_PCLK2;
  RCC_ClkInitStruct.SYSCLKSource = RCC_SYSCLKSOURCE_PLLCLK;
  RCC_ClkInitStruct.AHBCLKDivider = RCC_SYSCLK_DIV1;
  RCC_ClkInitStruct.APB1CLKDivider = RCC_HCLK_DIV4;
  RCC_ClkInitStruct.APB2CLKDivider = RCC_HCLK_DIV2;

  if (HAL_RCC_ClockConfig(&RCC_ClkInitStruct, FLASH_LATENCY_5) != HAL_OK)
  {
    Error_Handler();
  }
  PeriphClkInitStruct.PeriphClockSelection = RCC_PERIPHCLK_LTDC;
  PeriphClkInitStruct.PLLSAI.PLLSAIN = 216;
  PeriphClkInitStruct.PLLSAI.PLLSAIR = 2;
  PeriphClkInitStruct.PLLSAIDivR = RCC_PLLSAIDIVR_2;
  if (HAL_RCCEx_PeriphCLKConfig(&PeriphClkInitStruct) != HAL_OK)
  {
    Error_Handler();
  }
}

static void MX_DMA2D_Init(void)
{

  hdma2d.Instance = DMA2D;
  hdma2d.Init.Mode = DMA2D_M2M;
  hdma2d.Init.ColorMode = DMA2D_OUTPUT_ARGB8888;
  hdma2d.Init.OutputOffset = 0;
  hdma2d.LayerCfg[1].InputOffset = 0;
  hdma2d.LayerCfg[1].InputColorMode = DMA2D_INPUT_ARGB8888;
  hdma2d.LayerCfg[1].AlphaMode = DMA2D_NO_MODIF_ALPHA;
  hdma2d.LayerCfg[1].InputAlpha = 0;
  if (HAL_DMA2D_Init(&hdma2d) != HAL_OK)
  {
    Error_Handler();
  }
  if (HAL_DMA2D_ConfigLayer(&hdma2d, 1) != HAL_OK)
  {
    Error_Handler();
  }

}

static void MX_DSIHOST_DSI_Init(void)
{

  DSI_PLLInitTypeDef PLLInit = {0};
  DSI_HOST_TimeoutTypeDef HostTimeouts = {0};
  DSI_PHY_TimerTypeDef PhyTimings = {0};
  DSI_VidCfgTypeDef VidCfg = {0};

  hdsi.Instance = DSI;
  hdsi.Init.AutomaticClockLaneControl = DSI_AUTO_CLK_LANE_CTRL_DISABLE;
  hdsi.Init.TXEscapeCkdiv = 4;
  hdsi.Init.NumberOfLanes = DSI_TWO_DATA_LANES;
  PLLInit.PLLNDIV = 125;
  PLLInit.PLLIDF = DSI_PLL_IN_DIV2;
  PLLInit.PLLODF = DSI_PLL_OUT_DIV1;
  if (HAL_DSI_Init(&hdsi, &PLLInit) != HAL_OK)
  {
    Error_Handler();
  }
  HostTimeouts.TimeoutCkdiv = 1;
  HostTimeouts.HighSpeedTransmissionTimeout = 0;
  HostTimeouts.LowPowerReceptionTimeout = 0;
  HostTimeouts.HighSpeedReadTimeout = 0;
  HostTimeouts.LowPowerReadTimeout = 0;
  HostTimeouts.HighSpeedWriteTimeout = 0;
  HostTimeouts.HighSpeedWritePrespMode = DSI_HS_PM_DISABLE;
  HostTimeouts.LowPowerWriteTimeout = 0;
  HostTimeouts.BTATimeout = 0;
  if (HAL_DSI_ConfigHostTimeouts(&hdsi, &HostTimeouts) != HAL_OK)
  {
    Error_Handler();
  }
  PhyTimings.ClockLaneHS2LPTime = 28;
  PhyTimings.ClockLaneLP2HSTime = 33;
  PhyTimings.DataLaneHS2LPTime = 15;
  PhyTimings.DataLaneLP2HSTime = 25;
  PhyTimings.DataLaneMaxReadTime = 0;
  PhyTimings.StopWaitTime = 10;
  if (HAL_DSI_ConfigPhyTimer(&hdsi, &PhyTimings) != HAL_OK)
  {
    Error_Handler();
  }
  if (HAL_DSI_ConfigFlowControl(&hdsi, DSI_FLOW_CONTROL_BTA) != HAL_OK)
  {
    Error_Handler();
  }
  if (HAL_DSI_SetLowPowerRXFilter(&hdsi, 10000) != HAL_OK)
  {
    Error_Handler();
  }
  if (HAL_DSI_ConfigErrorMonitor(&hdsi, HAL_DSI_ERROR_NONE) != HAL_OK)
  {
    Error_Handler();
  }
  VidCfg.VirtualChannelID = 0;
  VidCfg.ColorCoding = DSI_RGB888;
  VidCfg.LooselyPacked = DSI_LOOSELY_PACKED_DISABLE;
  VidCfg.Mode = DSI_VID_MODE_NB_PULSES;
  VidCfg.PacketSize = 1;
  VidCfg.NumberOfChunks = 800;
  VidCfg.NullPacketSize = 0;
  VidCfg.HSPolarity = DSI_HSYNC_ACTIVE_LOW;
  VidCfg.VSPolarity = DSI_VSYNC_ACTIVE_LOW;
  VidCfg.DEPolarity = DSI_DATA_ENABLE_ACTIVE_HIGH;
  VidCfg.HorizontalSyncActive = 9;
  VidCfg.HorizontalBackPorch = 8;
  VidCfg.HorizontalLine = 950;
  VidCfg.VerticalSyncActive = 4;
  VidCfg.VerticalBackPorch = 2;
  VidCfg.VerticalFrontPorch = 2;
  VidCfg.VerticalActive = 480;
  VidCfg.LPCommandEnable = DSI_LP_COMMAND_DISABLE;
  VidCfg.LPLargestPacketSize = 0;
  VidCfg.LPVACTLargestPacketSize = 0;
  VidCfg.LPHorizontalFrontPorchEnable = DSI_LP_HFP_ENABLE;
  VidCfg.LPHorizontalBackPorchEnable = DSI_LP_HBP_ENABLE;
  VidCfg.LPVerticalActiveEnable = DSI_LP_VACT_ENABLE;
  VidCfg.LPVerticalFrontPorchEnable = DSI_LP_VFP_ENABLE;
  VidCfg.LPVerticalBackPorchEnable = DSI_LP_VBP_ENABLE;
  VidCfg.LPVerticalSyncActiveEnable = DSI_LP_VSYNC_ENABLE;
  VidCfg.FrameBTAAcknowledgeEnable = DSI_FBTAA_DISABLE;
  if (HAL_DSI_ConfigVideoMode(&hdsi, &VidCfg) != HAL_OK)
  {
    Error_Handler();
  }
  if (HAL_DSI_SetGenericVCID(&hdsi, 0) != HAL_OK)
  {
    Error_Handler();
  }

}

static void MX_I2C1_Init(void)
{

  hi2c1.Instance = I2C1;
  hi2c1.Init.ClockSpeed = 100000;
  hi2c1.Init.DutyCycle = I2C_DUTYCYCLE_2;
  hi2c1.Init.OwnAddress1 = 0;
  hi2c1.Init.AddressingMode = I2C_ADDRESSINGMODE_7BIT;
  hi2c1.Init.DualAddressMode = I2C_DUALADDRESS_DISABLE;
  hi2c1.Init.OwnAddress2 = 0;
  hi2c1.Init.GeneralCallMode = I2C_GENERALCALL_DISABLE;
  hi2c1.Init.NoStretchMode = I2C_NOSTRETCH_DISABLE;
  if (HAL_I2C_Init(&hi2c1) != HAL_OK)
  {
    Error_Handler();
  }

}

static void MX_I2C2_Init(void)
{

  hi2c2.Instance = I2C2;
  hi2c2.Init.ClockSpeed = 100000;
  hi2c2.Init.DutyCycle = I2C_DUTYCYCLE_2;
  hi2c2.Init.OwnAddress1 = 0;
  hi2c2.Init.AddressingMode = I2C_ADDRESSINGMODE_7BIT;
  hi2c2.Init.DualAddressMode = I2C_DUALADDRESS_DISABLE;
  hi2c2.Init.OwnAddress2 = 0;
  hi2c2.Init.GeneralCallMode = I2C_GENERALCALL_DISABLE;
  hi2c2.Init.NoStretchMode = I2C_NOSTRETCH_DISABLE;
  if (HAL_I2C_Init(&hi2c2) != HAL_OK)
  {
    Error_Handler();
  }

}

static void MX_LTDC_Init(void)
{

  LTDC_LayerCfgTypeDef pLayerCfg = {0};

  hltdc.Instance = LTDC;
  hltdc.Init.HSPolarity = LTDC_HSPOLARITY_AL;
  hltdc.Init.VSPolarity = LTDC_VSPOLARITY_AL;
  hltdc.Init.DEPolarity = LTDC_DEPOLARITY_AL;
  hltdc.Init.PCPolarity = LTDC_PCPOLARITY_IPC;
  hltdc.Init.HorizontalSync = 7;
  hltdc.Init.VerticalSync = 3;
  hltdc.Init.AccumulatedHBP = 14;
  hltdc.Init.AccumulatedVBP = 5;
  hltdc.Init.AccumulatedActiveW = 814;
  hltdc.Init.AccumulatedActiveH = 485;
  hltdc.Init.TotalWidth = 820;
  hltdc.Init.TotalHeigh = 487;
  hltdc.Init.Backcolor.Blue = 0;
  hltdc.Init.Backcolor.Green = 0;
  hltdc.Init.Backcolor.Red = 0;
  if (HAL_LTDC_Init(&hltdc) != HAL_OK)
  {
    Error_Handler();
  }
  pLayerCfg.WindowX0 = 0;
  pLayerCfg.WindowX1 = 0;
  pLayerCfg.WindowY0 = 0;
  pLayerCfg.WindowY1 = 0;
  pLayerCfg.PixelFormat = LTDC_PIXEL_FORMAT_RGB888;
  pLayerCfg.Alpha = 0;
  pLayerCfg.Alpha0 = 0;
  pLayerCfg.BlendingFactor1 = LTDC_BLENDING_FACTOR1_CA;
  pLayerCfg.BlendingFactor2 = LTDC_BLENDING_FACTOR2_CA;
  pLayerCfg.FBStartAdress = 0;
  pLayerCfg.ImageWidth = 0;
  pLayerCfg.ImageHeight = 0;
  pLayerCfg.Backcolor.Blue = 0;
  pLayerCfg.Backcolor.Green = 0;
  pLayerCfg.Backcolor.Red = 0;
  if (HAL_LTDC_ConfigLayer(&hltdc, &pLayerCfg, 0) != HAL_OK)
  {
    Error_Handler();
  }

}

static void MX_TIM1_Init(void)
{

  TIM_ClockConfigTypeDef sClockSourceConfig = {0};
  TIM_MasterConfigTypeDef sMasterConfig = {0};

  htim1.Instance = TIM1;
  htim1.Init.Prescaler = 0;
  htim1.Init.CounterMode = TIM_COUNTERMODE_UP;
  htim1.Init.Period = 0;
  htim1.Init.ClockDivision = TIM_CLOCKDIVISION_DIV1;
  htim1.Init.RepetitionCounter = 0;
  htim1.Init.AutoReloadPreload = TIM_AUTORELOAD_PRELOAD_DISABLE;
  if (HAL_TIM_Base_Init(&htim1) != HAL_OK)
  {
    Error_Handler();
  }
  sClockSourceConfig.ClockSource = TIM_CLOCKSOURCE_INTERNAL;
  if (HAL_TIM_ConfigClockSource(&htim1, &sClockSourceConfig) != HAL_OK)
  {
    Error_Handler();
  }
  sMasterConfig.MasterOutputTrigger = TIM_TRGO_RESET;
  sMasterConfig.MasterSlaveMode = TIM_MASTERSLAVEMODE_DISABLE;
  if (HAL_TIMEx_MasterConfigSynchronization(&htim1, &sMasterConfig) != HAL_OK)
  {
    Error_Handler();
  }

}

/* FMC initialization function */
static void MX_FMC_Init(void)
{

  FMC_SDRAM_TimingTypeDef SdramTiming = {0};

  /** Perform the SDRAM1 memory initialization sequence
  */
  hsdram1.Instance = FMC_SDRAM_DEVICE;
  /* hsdram1.Init */
  hsdram1.Init.SDBank = FMC_SDRAM_BANK1;
  hsdram1.Init.ColumnBitsNumber = FMC_SDRAM_COLUMN_BITS_NUM_8;
  hsdram1.Init.RowBitsNumber = FMC_SDRAM_ROW_BITS_NUM_12;
  hsdram1.Init.MemoryDataWidth = FMC_SDRAM_MEM_BUS_WIDTH_32;
  hsdram1.Init.InternalBankNumber = FMC_SDRAM_INTERN_BANKS_NUM_4;
  hsdram1.Init.CASLatency = FMC_SDRAM_CAS_LATENCY_3;
  hsdram1.Init.WriteProtection = FMC_SDRAM_WRITE_PROTECTION_DISABLE;
  hsdram1.Init.SDClockPeriod = FMC_SDRAM_CLOCK_PERIOD_2;
  hsdram1.Init.ReadBurst = FMC_SDRAM_RBURST_ENABLE;
  hsdram1.Init.ReadPipeDelay = FMC_SDRAM_RPIPE_DELAY_0;
  /* SdramTiming */
  SdramTiming.LoadToActiveDelay = 2;
  SdramTiming.ExitSelfRefreshDelay = 7;
  SdramTiming.SelfRefreshTime = 4;
  SdramTiming.RowCycleDelay = 7;
  SdramTiming.WriteRecoveryTime = 3;
  SdramTiming.RPDelay = 2;
  SdramTiming.RCDDelay = 2;

  if (HAL_SDRAM_Init(&hsdram1, &SdramTiming) != HAL_OK)
  {
    Error_Handler( );
  }

}

static void MX_GPIO_Init(void)
{
  GPIO_InitTypeDef GPIO_InitStruct = {0};

  /* GPIO Ports Clock Enable */
  __HAL_RCC_GPIOE_CLK_ENABLE();
  __HAL_RCC_GPIOG_CLK_ENABLE();
  __HAL_RCC_GPIOB_CLK_ENABLE();
  __HAL_RCC_GPIOC_CLK_ENABLE();
  __HAL_RCC_GPIOA_CLK_ENABLE();
  __HAL_RCC_GPIOD_CLK_ENABLE();
  __HAL_RCC_GPIOI_CLK_ENABLE();
  __HAL_RCC_GPIOF_CLK_ENABLE();
  __HAL_RCC_GPIOK_CLK_ENABLE();
  __HAL_RCC_GPIOH_CLK_ENABLE();
  __HAL_RCC_GPIOJ_CLK_ENABLE();

  /*Configure GPIO pin Output Level */
  HAL_GPIO_WritePin(GPIOE, SPKR_HP_Pin|AUDIO_RST_Pin, GPIO_PIN_RESET);

  /*Configure GPIO pin Output Level */
  HAL_GPIO_WritePin(GPIOD, LED3_Pin|LED2_Pin, GPIO_PIN_RESET);

  /*Configure GPIO pin Output Level */
  HAL_GPIO_WritePin(LED4_GPIO_Port, LED4_Pin, GPIO_PIN_RESET);

  /*Configure GPIO pin Output Level */
  HAL_GPIO_WritePin(LED1_GPIO_Port, LED1_Pin, GPIO_PIN_RESET);

  /*Configure GPIO pin Output Level */
  HAL_GPIO_WritePin(GPIOB, OTG_FS1_PowerSwitchOn_Pin|EXT_RESET_Pin, GPIO_PIN_RESET);

  /*Configure GPIO pin Output Level */
  HAL_GPIO_WritePin(GPIOH, GPIO_PIN_7, GPIO_PIN_RESET);

  /*Configure GPIO pin Output Level */
  HAL_GPIO_WritePin(LCD_BL_CTRL_GPIO_Port, LCD_BL_CTRL_Pin, GPIO_PIN_RESET);

  /*Configure GPIO pins : SAI1_FSA_Pin SAI1_SCKA_Pin */
  GPIO_InitStruct.Pin = SAI1_FSA_Pin|SAI1_SCKA_Pin;
  GPIO_InitStruct.Mode = GPIO_MODE_AF_PP;
  GPIO_InitStruct.Pull = GPIO_NOPULL;
  GPIO_InitStruct.Speed = GPIO_SPEED_FREQ_LOW;
  GPIO_InitStruct.Alternate = GPIO_AF6_SAI1;
  HAL_GPIO_Init(GPIOE, &GPIO_InitStruct);

  /*Configure GPIO pins : SPKR_HP_Pin AUDIO_RST_Pin */
  GPIO_InitStruct.Pin = SPKR_HP_Pin|AUDIO_RST_Pin;
  GPIO_InitStruct.Mode = GPIO_MODE_OUTPUT_PP;
  GPIO_InitStruct.Pull = GPIO_NOPULL;
  GPIO_InitStruct.Speed = GPIO_SPEED_FREQ_LOW;
  HAL_GPIO_Init(GPIOE, &GPIO_InitStruct);

  /*Configure GPIO pins : ARDUINO_USART6_TX_Pin USART6_RX_Pin */
  GPIO_InitStruct.Pin = ARDUINO_USART6_TX_Pin|USART6_RX_Pin;
  GPIO_InitStruct.Mode = GPIO_MODE_AF_PP;
  GPIO_InitStruct.Pull = GPIO_NOPULL;
  GPIO_InitStruct.Speed = GPIO_SPEED_FREQ_VERY_HIGH;
  GPIO_InitStruct.Alternate = GPIO_AF8_USART6;
  HAL_GPIO_Init(GPIOG, &GPIO_InitStruct);

  /*Configure GPIO pin : I2S3_CK_Pin */
  GPIO_InitStruct.Pin = I2S3_CK_Pin;
  GPIO_InitStruct.Mode = GPIO_MODE_AF_PP;
  GPIO_InitStruct.Pull = GPIO_NOPULL;
  GPIO_InitStruct.Speed = GPIO_SPEED_FREQ_LOW;
  GPIO_InitStruct.Alternate = GPIO_AF6_SPI3;
  HAL_GPIO_Init(I2S3_CK_GPIO_Port, &GPIO_InitStruct);

  /*Configure GPIO pins : uSD_CLK_Pin uSD_D3_Pin uSD_D2_Pin uSD_D1_Pin
                           uSD_D0_Pin */
  GPIO_InitStruct.Pin = uSD_CLK_Pin|uSD_D3_Pin|uSD_D2_Pin|uSD_D1_Pin
                          |uSD_D0_Pin;
  GPIO_InitStruct.Mode = GPIO_MODE_AF_PP;
  GPIO_InitStruct.Pull = GPIO_NOPULL;
  GPIO_InitStruct.Speed = GPIO_SPEED_FREQ_VERY_HIGH;
  GPIO_InitStruct.Alternate = GPIO_AF12_SDIO;
  HAL_GPIO_Init(GPIOC, &GPIO_InitStruct);

  /*Configure GPIO pin : OTG_FS1_OverCurrent_Pin */
  GPIO_InitStruct.Pin = OTG_FS1_OverCurrent_Pin;
  GPIO_InitStruct.Mode = GPIO_MODE_IT_RISING;
  GPIO_InitStruct.Pull = GPIO_NOPULL;
  HAL_GPIO_Init(OTG_FS1_OverCurrent_GPIO_Port, &GPIO_InitStruct);

  /*Configure GPIO pin : QSPI_BK1_NCS_Pin */
  GPIO_InitStruct.Pin = QSPI_BK1_NCS_Pin;
  GPIO_InitStruct.Mode = GPIO_MODE_AF_PP;
  GPIO_InitStruct.Pull = GPIO_NOPULL;
  GPIO_InitStruct.Speed = GPIO_SPEED_FREQ_VERY_HIGH;
  GPIO_InitStruct.Alternate = GPIO_AF10_QSPI;
  HAL_GPIO_Init(QSPI_BK1_NCS_GPIO_Port, &GPIO_InitStruct);

  /*Configure GPIO pin : MIC_DATA_Pin */
  GPIO_InitStruct.Pin = MIC_DATA_Pin;
  GPIO_InitStruct.Mode = GPIO_MODE_AF_PP;
  GPIO_InitStruct.Pull = GPIO_NOPULL;
  GPIO_InitStruct.Speed = GPIO_SPEED_FREQ_LOW;
  GPIO_InitStruct.Alternate = GPIO_AF6_SAI1;
  HAL_GPIO_Init(MIC_DATA_GPIO_Port, &GPIO_InitStruct);

  /*Configure GPIO pins : USB_FS1_P_Pin USB_FS1_N_Pin USB_FS1_ID_Pin */
  GPIO_InitStruct.Pin = USB_FS1_P_Pin|USB_FS1_N_Pin|USB_FS1_ID_Pin;
  GPIO_InitStruct.Mode = GPIO_MODE_AF_PP;
  GPIO_InitStruct.Pull = GPIO_NOPULL;
  GPIO_InitStruct.Speed = GPIO_SPEED_FREQ_VERY_HIGH;
  GPIO_InitStruct.Alternate = GPIO_AF10_OTG_FS;
  HAL_GPIO_Init(GPIOA, &GPIO_InitStruct);

  /*Configure GPIO pins : LED3_Pin LED2_Pin */
  GPIO_InitStruct.Pin = LED3_Pin|LED2_Pin;
  GPIO_InitStruct.Mode = GPIO_MODE_OUTPUT_OD;
  GPIO_InitStruct.Pull = GPIO_NOPULL;
  GPIO_InitStruct.Speed = GPIO_SPEED_FREQ_LOW;
  HAL_GPIO_Init(GPIOD, &GPIO_InitStruct);

  /*Configure GPIO pin : LED4_Pin */
  GPIO_InitStruct.Pin = LED4_Pin;
  GPIO_InitStruct.Mode = GPIO_MODE_OUTPUT_OD;
  GPIO_InitStruct.Pull = GPIO_NOPULL;
  GPIO_InitStruct.Speed = GPIO_SPEED_FREQ_LOW;
  HAL_GPIO_Init(LED4_GPIO_Port, &GPIO_InitStruct);

  /*Configure GPIO pin : uSD_CMD_Pin */
  GPIO_InitStruct.Pin = uSD_CMD_Pin;
  GPIO_InitStruct.Mode = GPIO_MODE_AF_PP;
  GPIO_InitStruct.Pull = GPIO_NOPULL;
  GPIO_InitStruct.Speed = GPIO_SPEED_FREQ_VERY_HIGH;
  GPIO_InitStruct.Alternate = GPIO_AF12_SDIO;
  HAL_GPIO_Init(uSD_CMD_GPIO_Port, &GPIO_InitStruct);

  /*Configure GPIO pin : VBUS_FS1_Pin */
  GPIO_InitStruct.Pin = VBUS_FS1_Pin;
  GPIO_InitStruct.Mode = GPIO_MODE_AF_PP;
  GPIO_InitStruct.Pull = GPIO_NOPULL;
  HAL_GPIO_Init(VBUS_FS1_GPIO_Port, &GPIO_InitStruct);

  /*Configure GPIO pin : SAI1_MCLKA_Pin */
  GPIO_InitStruct.Pin = SAI1_MCLKA_Pin;
  GPIO_InitStruct.Mode = GPIO_MODE_AF_PP;
  GPIO_InitStruct.Pull = GPIO_NOPULL;
  GPIO_InitStruct.Speed = GPIO_SPEED_FREQ_LOW;
  GPIO_InitStruct.Alternate = GPIO_AF6_SAI1;
  HAL_GPIO_Init(SAI1_MCLKA_GPIO_Port, &GPIO_InitStruct);

  /*Configure GPIO pin : LED1_Pin */
  GPIO_InitStruct.Pin = LED1_Pin;
  GPIO_InitStruct.Mode = GPIO_MODE_OUTPUT_OD;
  GPIO_InitStruct.Pull = GPIO_NOPULL;
  GPIO_InitStruct.Speed = GPIO_SPEED_FREQ_LOW;
  HAL_GPIO_Init(LED1_GPIO_Port, &GPIO_InitStruct);

  /*Configure GPIO pins : QSPI_BK1_IO2_Pin QSPI_BK1_IO3_Pin QSPI_CLK_Pin */
  GPIO_InitStruct.Pin = QSPI_BK1_IO2_Pin|QSPI_BK1_IO3_Pin|QSPI_CLK_Pin;
  GPIO_InitStruct.Mode = GPIO_MODE_AF_PP;
  GPIO_InitStruct.Pull = GPIO_NOPULL;
  GPIO_InitStruct.Speed = GPIO_SPEED_FREQ_VERY_HIGH;
  GPIO_InitStruct.Alternate = GPIO_AF9_QSPI;
  HAL_GPIO_Init(GPIOF, &GPIO_InitStruct);

  /*Configure GPIO pins : QSPI_BK1_IO1_Pin QSPI_BK1_IO0_Pin */
  GPIO_InitStruct.Pin = QSPI_BK1_IO1_Pin|QSPI_BK1_IO0_Pin;
  GPIO_InitStruct.Mode = GPIO_MODE_AF_PP;
  GPIO_InitStruct.Pull = GPIO_NOPULL;
  GPIO_InitStruct.Speed = GPIO_SPEED_FREQ_VERY_HIGH;
  GPIO_InitStruct.Alternate = GPIO_AF10_QSPI;
  HAL_GPIO_Init(GPIOF, &GPIO_InitStruct);

  /*Configure GPIO pins : OTG_FS1_PowerSwitchOn_Pin EXT_RESET_Pin */
  GPIO_InitStruct.Pin = OTG_FS1_PowerSwitchOn_Pin|EXT_RESET_Pin;
  GPIO_InitStruct.Mode = GPIO_MODE_OUTPUT_PP;
  GPIO_InitStruct.Pull = GPIO_NOPULL;
  GPIO_InitStruct.Speed = GPIO_SPEED_FREQ_LOW;
  HAL_GPIO_Init(GPIOB, &GPIO_InitStruct);

  /*Configure GPIO pin : MIC_CK_Pin */
  GPIO_InitStruct.Pin = MIC_CK_Pin;
  GPIO_InitStruct.Mode = GPIO_MODE_AF_PP;
  GPIO_InitStruct.Pull = GPIO_NOPULL;
  GPIO_InitStruct.Speed = GPIO_SPEED_FREQ_LOW;
  GPIO_InitStruct.Alternate = GPIO_AF2_TIM4;
  HAL_GPIO_Init(MIC_CK_GPIO_Port, &GPIO_InitStruct);

  /*Configure GPIO pin : uSD_Detect_Pin */
  GPIO_InitStruct.Pin = uSD_Detect_Pin;
  GPIO_InitStruct.Mode = GPIO_MODE_INPUT;
  GPIO_InitStruct.Pull = GPIO_NOPULL;
  HAL_GPIO_Init(uSD_Detect_GPIO_Port, &GPIO_InitStruct);

  /*Configure GPIO pin : LCD_INT_Pin */
  GPIO_InitStruct.Pin = LCD_INT_Pin;
  GPIO_InitStruct.Mode = GPIO_MODE_IT_RISING;
  GPIO_InitStruct.Pull = GPIO_NOPULL;
  HAL_GPIO_Init(LCD_INT_GPIO_Port, &GPIO_InitStruct);

  /*Configure GPIO pin : PH7 */
  GPIO_InitStruct.Pin = GPIO_PIN_7;
  GPIO_InitStruct.Mode = GPIO_MODE_OUTPUT_PP;
  GPIO_InitStruct.Pull = GPIO_NOPULL;
  GPIO_InitStruct.Speed = GPIO_SPEED_FREQ_LOW;
  HAL_GPIO_Init(GPIOH, &GPIO_InitStruct);

  /*Configure GPIO pins : STLK_RX_Pin STLK_TX_Pin */
  GPIO_InitStruct.Pin = STLK_RX_Pin|STLK_TX_Pin;
  GPIO_InitStruct.Mode = GPIO_MODE_AF_PP;
  GPIO_InitStruct.Pull = GPIO_PULLUP;
  GPIO_InitStruct.Speed = GPIO_SPEED_FREQ_VERY_HIGH;
  GPIO_InitStruct.Alternate = GPIO_AF7_USART3;
  HAL_GPIO_Init(GPIOB, &GPIO_InitStruct);

  /*Configure GPIO pin : LCD_BL_CTRL_Pin */
  GPIO_InitStruct.Pin = LCD_BL_CTRL_Pin;
  GPIO_InitStruct.Mode = GPIO_MODE_OUTPUT_PP;
  GPIO_InitStruct.Pull = GPIO_NOPULL;
  GPIO_InitStruct.Speed = GPIO_SPEED_FREQ_LOW;
  HAL_GPIO_Init(LCD_BL_CTRL_GPIO_Port, &GPIO_InitStruct);

}

 /**
  * @brief  Period elapsed callback in non blocking mode
  * @note   This function is called  when TIM6 interrupt took place, inside
  * HAL_TIM_IRQHandler(). It makes a direct call to HAL_IncTick() to increment
  * a global variable "uwTick" used as application time base.
  * @param  htim : TIM handle
  * @retval None
  */
void HAL_TIM_PeriodElapsedCallback(TIM_HandleTypeDef *htim)
{
  if (htim->Instance == TIM6) {
    HAL_IncTick();
  }
}

void Error_Handler(void)
{
}

/************************ (C) COPYRIGHT STMicroelectronics *****END OF FILE****/
